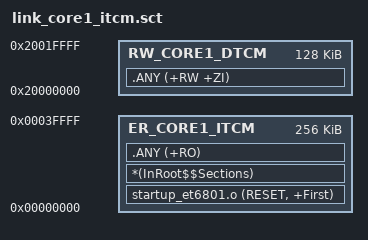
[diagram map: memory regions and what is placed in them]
LR_CORE1_ITCM 0x00000000 0x00040000
{
    ER_CORE1_ITCM 0x00000000 0x00040000
    {
        startup_et6801.o (RESET, +First)
        *(InRoot$$Sections)
        .ANY (+RO)
    }

    RW_CORE1_DTCM 0x20000000 0x00020000
    {
        .ANY (+RW +ZI)
    }
}
